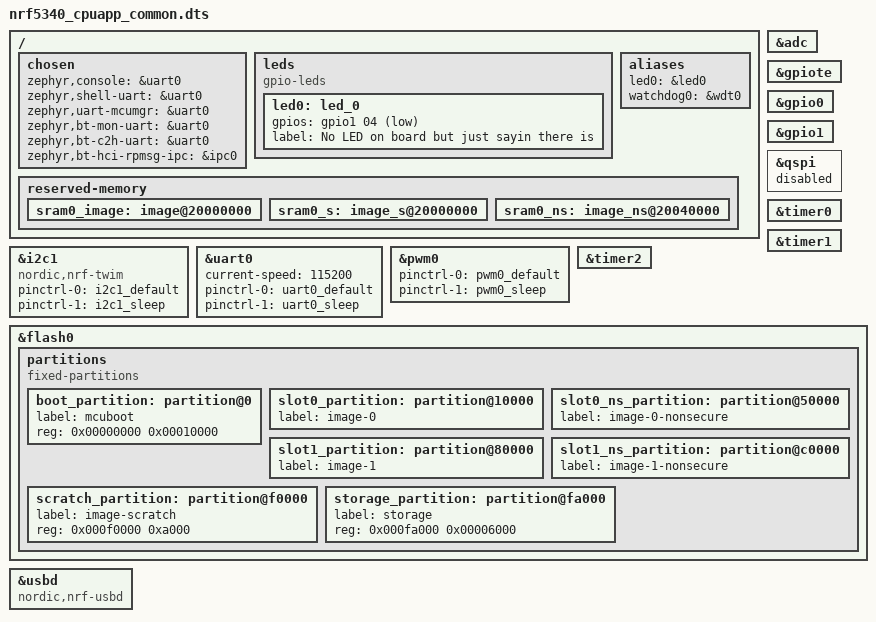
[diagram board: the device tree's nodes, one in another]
/*
 * Copyright (c) 2019-2020 Nordic Semiconductor ASA
 *
 * SPDX-License-Identifier: Apache-2.0
 */
#include "nrf5340_cpuapp_common-pinctrl.dtsi"
#include "arduino_pro_micro_pins.dtsi"

/ {

	chosen {
		zephyr,console = &uart0;
		zephyr,shell-uart = &uart0;
		zephyr,uart-mcumgr = &uart0;
		zephyr,bt-mon-uart = &uart0;
		zephyr,bt-c2h-uart = &uart0;
		zephyr,bt-hci-rpmsg-ipc = &ipc0;
	};

	leds {
		compatible = "gpio-leds";
		led0: led_0 {
			gpios = <&gpio1 04 GPIO_ACTIVE_LOW>;
			label = "No LED on board but just sayin there is";
		};
	};

	/* These aliases are provided for compatibility with samples */
	aliases {
		led0 = &led0;

		watchdog0 = &wdt0;
	};
};

&adc {
	status = "okay";
};

&gpiote {
	status = "okay";
};

&gpio0 {
	status = "okay";
};

&gpio1 {
	status = "okay";
};

&i2c1 {
	compatible = "nordic,nrf-twim";
	status = "okay";
	pinctrl-0 = <&i2c1_default>;
	pinctrl-1 = <&i2c1_sleep>;
	pinctrl-names = "default", "sleep";
};

&uart0 {
	status = "okay";
	current-speed = <115200>;
	pinctrl-0 = <&uart0_default>;
	pinctrl-1 = <&uart0_sleep>;
	pinctrl-names = "default", "sleep";
};

&pwm0 {
	status = "okay";
	pinctrl-0 = <&pwm0_default>;
	pinctrl-1 = <&pwm0_sleep>;
	pinctrl-names = "default", "sleep";
};

&qspi {
	status = "disabled";
};

&timer0 {
	status = "okay";
};

&timer1 {
	status = "okay";
};

&timer2 {
	status = "okay";
};


&flash0 {

	partitions {
		compatible = "fixed-partitions";
		#address-cells = <1>;
		#size-cells = <1>;

		boot_partition: partition@0 {
			label = "mcuboot";
			reg = <0x00000000 0x00010000>;
		};
		slot0_partition: partition@10000 {
			label = "image-0";
		};
		slot0_ns_partition: partition@50000 {
			label = "image-0-nonsecure";
		};
		slot1_partition: partition@80000 {
			label = "image-1";
		};
		slot1_ns_partition: partition@c0000 {
			label = "image-1-nonsecure";
		};
		scratch_partition: partition@f0000 {
			label = "image-scratch";
			reg = <0x000f0000 0xa000>;
		};
		storage_partition: partition@fa000 {
			label = "storage";
			reg = <0x000fa000 0x00006000>;
		};
	};
};

zephyr_udc0: &usbd {
	compatible = "nordic,nrf-usbd";
	status = "okay";
};

/ {

	reserved-memory {
		#address-cells = <1>;
		#size-cells = <1>;
		ranges;

		sram0_image: image@20000000 {
			/* Zephyr image(s) memory */
		};

		sram0_s: image_s@20000000 {
			/* Secure image memory */
		};

		sram0_ns: image_ns@20040000 {
			/* Non-Secure image memory */
		};
	};
};

/* Include partition configuration file */
#include "nrf5340_cpuapp_partition_conf.dts"
